VERSION ""

NS_ :

BS_:

BU_: Pegasus Marvel Laptop Stark Xavier stark ULT ECC STR DCDC

BO_ 3221225472 VECTOR__INDEPENDENT_SIG_MSG: 0 Vector__XXX
 SG_ charger_requested_current : 23|16@0+ (0.1,0) [0|255] "" Vector__XXX
 SG_ charger_requested_voltage : 7|16@0+ (0.1,0) [0|255] "" Vector__XXX
 SG_ vehicle_display_soc : 7|16@0+ (0.1,0) [0|0] "" Vector__XXX
 SG_ controller_speed : 39|16@0+ (0.1,0) [0|65535] "" Vector__XXX
 SG_ charger_is_gun_connected : 48|1@1+ (1,0) [0|2] "" Vector__XXX
 SG_ charger_type : 52|2@1+ (1,0) [0|3] "" Vector__XXX
 SG_ vehicle_state : 63|8@0+ (1,0) [0|10] "" Vector__XXX
 SG_ vehicle_calculated_odo : 23|32@0+ (0.01,0) [0|429496729.5] "Km" Vector__XXX
 SG_ vehicle_stark_ticks : 7|32@0+ (1,0) [0|-1] "" Vector__XXX
 SG_ telemetry_start_index : 39|32@0+ (1,0) [0|-1] "" Vector__XXX
 SG_ vehicle_igni_debounce_count : 39|32@0+ (1,0) [0|-1] "" Vector__XXX
 SG_ vehicle_igni_cycle_count : 7|32@0+ (1,0) [0|-1] "" Vector__XXX
 SG_ derived_param_cycle_count : 39|32@0+ (0.01,0) [0|-1] "" Vector__XXX
 SG_ battery_max_voltage : 23|16@0+ (0.1,0) [0|6553.5] "" Vector__XXX
 SG_ battery_min_voltage : 7|16@0+ (0.1,0) [0|6553.5] "" Vector__XXX
 SG_ vcu_onboard_temperature : 39|16@0+ (0.1,0) [0|6553.5] "C" Vector__XXX
 SG_ vcu_c3_box_temperature : 55|16@0+ (0.1,0) [0|6553.5] "C" Vector__XXX
 SG_ vcu_ambient_temperature : 23|16@0+ (0.1,0) [0|6553.5] "C" Vector__XXX
 SG_ vehicle_gpio_peripheral : 7|16@0+ (1,0) [0|65535] "" Vector__XXX
 SG_ vcu_uid1 : 7|64@0+ (1,0) [0|1.8446744074E+19] "" Vector__XXX
 SG_ vcu_uid2 : 7|32@0+ (1,0) [0|-1] "" Vector__XXX
 SG_ arc_reactor_status : 52|2@1+ (1,0) [0|3] "" Vector__XXX
 SG_ charger_is_charging : 50|1@1+ (1,0) [0|1] "" Vector__XXX
 SG_ charger_safe_charging_flag : 49|1@1+ (1,0) [0|1] "" Vector__XXX
 SG_ charger_disable_flag : 48|1@1+ (1,0) [0|1] "" Vector__XXX
 SG_ vehicle_sleep_flag : 51|1@1+ (1,0) [0|1] "" Vector__XXX
 SG_ derived_param_wh_km : 39|16@0+ (0.1,0) [0|6553.5] "" Vector__XXX
 SG_ vehicle_time_to_sleep : 7|32@0+ (1,0) [0|-1] "" Vector__XXX
 SG_ controller_data_type : 55|1@1+ (1,0) [0|0] "" Vector__XXX
 SG_ battery_bms_data_type : 54|1@1+ (1,0) [0|0] "" Vector__XXX
 SG_ vehicle_ecu_manifest_crc : 39|32@0+ (1,0) [0|-1] "" Vector__XXX
 SG_ vehicle_manifest_crc : 7|32@0+ (1,0) [0|-1] "" Vector__XXX
 SG_ vcu_accel_roll : 55|16@0- (0.01,0) [-32768|32767] "" Vector__XXX
 SG_ vcu_gyro_z : 39|16@0- (0.01,0) [-32768|32767] "" Vector__XXX
 SG_ vcu_gyro_y : 23|16@0- (0.01,0) [-32768|32767] "" Vector__XXX
 SG_ vcu_gyro_x : 7|16@0- (0.01,0) [-327.68|327.67] "" Vector__XXX
 SG_ vcu_accel_pitch : 55|16@0- (0.01,0) [-32768|32767] "" Vector__XXX
 SG_ vcu_accel_z : 39|16@0- (0.01,0) [-32768|32767] "" Vector__XXX
 SG_ vcu_accel_y : 23|16@0- (0.01,0) [-32768|32767] "" Vector__XXX
 SG_ vcu_accel_x : 7|16@0- (0.01,0) [-327.68|327.67] "" Vector__XXX
 SG_ vcu_mag_z : 39|16@0- (0.1,0) [-32768|32767] "" Vector__XXX
 SG_ vcu_mag_y : 23|16@0- (0.1,0) [-32768|32767] "" Vector__XXX
 SG_ vcu_mag_x : 7|16@0- (0.1,0) [-327.68|327.67] "" Vector__XXX
 SG_ vcu_angle_z : 39|16@0- (0.1,0) [-32768|32767] "" Vector__XXX
 SG_ vcu_angle_y : 23|16@0- (0.1,0) [-32768|32767] "" Vector__XXX
 SG_ vcu_angle_x : 7|16@0- (0.1,0) [-327.68|327.67] "" Vector__XXX
 SG_ error_1 : 7|64@0+ (1,0) [-32768|32767] "" Vector__XXX
 SG_ error_2 : 7|32@0+ (1,0) [-32768|32767] "" Vector__XXX
 SG_ unknown_error_1 : 39|16@0+ (1,0) [-32768|32767] "" Vector__XXX
 SG_ unknown_error_2 : 55|16@0+ (1,0) [-327.68|327.67] "" Vector__XXX
 SG_ vehicle_calculated_trip : 32|32@1+ (0.1,0) [0|0] ""  Xavier
 SG_ vehicle_ttfc : 32|16@1+ (1,0) [0|0] ""  Xavier
 SG_ vehicle_range : 16|16@1+ (0.1,0) [0|0] ""  Xavier
 SG_ vehicle_immob_state : 45|1@1+ (1,0) [0|1] "" Vector__XXX
 SG_ vehicle_thermal_runaway_flag : 22|1@1+ (1,0) [0|1] "" Vector__XXX
 SG_ vehicle_digital_lock_state : 44|1@1+ (1,0) [0|1] "" Vector__XXX
 SG_ git_shaw : 16|32@1+ (1,0) [0|-1] ""  Laptop
 SG_ device_id : 0|8@1+ (1,0) [0|255] ""  Laptop
 SG_ sim_16_20 : 0|32@1+ (1,0) [0|-1] ""  Laptop
 SG_ sim_0_16 : 0|64@1+ (1,0) [0|9.2233720369E+18] ""  Laptop
 SG_ imei : 0|64@1+ (1,0) [0|9.2233720369E+18] ""  Laptop
 SG_ certificate_state : 48|8@1+ (1,0) [0|255] ""  Laptop
 SG_ error_state : 40|8@1+ (1,0) [0|255] ""  Laptop
 SG_ system_state : 32|8@1+ (1,0) [0|255] ""  Laptop
 SG_ ota_state : 24|8@1+ (1,0) [0|255] ""  Laptop
 SG_ mqtt_publish_value : 16|8@1+ (1,0) [0|255] ""  Laptop
 SG_ http_state : 8|8@1+ (1,0) [0|255] ""  Laptop
 SG_ network_state : 0|8@1+ (1,0) [0|0] ""  Laptop
 SG_ battery_bms_temperature_9 : 16|8@1+ (1,0) [0|255] "C" Vector__XXX
 SG_ battery_bms_temperature_8 : 8|8@1+ (1,0) [0|255] "C" Vector__XXX
 SG_ battery_bms_temperature_7 : 0|8@1+ (1,0) [0|255] "C" Vector__XXX
 SG_ battery_bms_temperature_11 : 32|8@1+ (1,0) [0|255] "C" Vector__XXX
 SG_ battery_bms_temperature_10 : 24|8@1+ (1,0) [0|255] "C" Vector__XXX
 SG_ battery_bms_temperature_minimum : 40|8@1- (1,0) [-40|125] "C" Vector__XXX
 SG_ battery_bms_temperature_maximum : 48|8@1- (1,0) [-40|125] "C" Vector__XXX
 SG_ battery_bms_temperature_average : 56|8@1- (1,0) [-40|125] "C" Vector__XXX
 SG_ battery_bms_max_capacity : 0|16@1+ (0.1,0) [0|6553.5] "Ah" Vector__XXX
 SG_ battery_cmu_2_balancing_mask : 48|16@1+ (1,0) [0|65535] "" Vector__XXX
 SG_ battery_cmu_1_balancing_mask : 32|16@1+ (1,0) [0|65535] "" Vector__XXX
 SG_ battery_cmu_3_balancing_mask : 48|16@1+ (1,0) [0|65535] "" Vector__XXX
 SG_ battery_c_10_v_4 : 16|16@1+ (0.1,0) [0|6553.5] "mV" Vector__XXX
 SG_ battery_c_10_v_2 : 0|16@1+ (0.1,0) [0|6553.5] "mV" Vector__XXX
 SG_ battery_voltage_min_cmu : 32|8@1+ (1,0) [0|255] "" Vector__XXX
 SG_ battery_voltage_min_cell : 40|8@1+ (1,0) [0|255] "" Vector__XXX
 SG_ battery_voltage_max_cmu : 48|8@1+ (1,0) [0|255] "" Vector__XXX
 SG_ battery_voltage_max_cell : 56|8@1+ (1,0) [0|255] "" Vector__XXX
 SG_ battery_c_9_v_9 : 48|16@1+ (0.1,0) [0|6553.5] "mV" Vector__XXX
 SG_ battery_c_9_v_7 : 32|16@1+ (0.1,0) [0|6553.5] "mV" Vector__XXX
 SG_ battery_c_9_v_5 : 16|16@1+ (0.1,0) [0|6553.5] "mV" Vector__XXX
 SG_ battery_c_9_v_3 : 0|16@1+ (0.1,0) [0|6553.5] "mV" Vector__XXX
 SG_ battery_c_9_v_1 : 48|16@1+ (0.1,0) [0|6553.5] "mV" Vector__XXX
 SG_ battery_c_8_v_8 : 32|16@1+ (0.1,0) [0|6553.5] "mV" Vector__XXX
 SG_ battery_c_8_v_6 : 16|16@1+ (0.1,0) [0|6553.5] "mV" Vector__XXX
 SG_ battery_c_8_v_4 : 0|16@1+ (0.1,0) [0|6553.5] "mV" Vector__XXX
 SG_ battery_c_8_v_2 : 48|16@1+ (0.1,0) [0|6553.5] "mV" Vector__XXX
 SG_ battery_c_7_v_9 : 32|16@1+ (0.1,0) [0|6553.5] "mV" Vector__XXX
 SG_ battery_c_7_v_7 : 16|16@1+ (0.1,0) [0|6553.5] "mV" Vector__XXX
 SG_ battery_c_7_v_5 : 0|16@1+ (0.1,0) [0|6553.5] "mV" Vector__XXX
 SG_ battery_c_7_v_3 : 48|16@1+ (0.1,0) [0|6553.5] "mV" Vector__XXX
 SG_ battery_c_7_v_1 : 32|16@1+ (0.1,0) [0|6553.5] "mV" Vector__XXX
 SG_ battery_c_6_v_11 : 16|16@1+ (0.1,0) [0|6553.5] "mV" Vector__XXX
 SG_ battery_c_6_v_9 : 0|16@1+ (0.1,0) [0|6553.5] "mV" Vector__XXX
 SG_ battery_c_6_v_7 : 48|16@1+ (0.1,0) [0|6553.5] "mV" Vector__XXX
 SG_ battery_c_6_v_5 : 32|16@1+ (0.1,0) [0|6553.5] "mV" Vector__XXX
 SG_ battery_c_6_v_3 : 16|16@1+ (0.1,0) [0|6553.5] "mV" Vector__XXX
 SG_ battery_c_6_v_1 : 0|16@1+ (0.1,0) [0|6553.5] "mV" Vector__XXX
 SG_ battery_c_5_v_3 : 48|16@1+ (0.1,0) [0|6553.5] "mV" Vector__XXX
 SG_ battery_c_5_v_1 : 32|16@1+ (0.1,0) [0|6553.5] "mV" Vector__XXX
 SG_ battery_c_4_v_8 : 16|16@1+ (0.1,0) [0|6553.5] "mV" Vector__XXX
 SG_ battery_c_4_v_6 : 0|16@1+ (0.1,0) [0|6553.5] "mV" Vector__XXX
 SG_ battery_c_5_v_11 : 48|16@1+ (0.1,0) [0|6553.5] "mV" Vector__XXX
 SG_ battery_c_5_v_9 : 32|16@1+ (0.1,0) [0|6553.5] "mV" Vector__XXX
 SG_ battery_c_5_v_7 : 16|16@1+ (0.1,0) [0|6553.5] "mV" Vector__XXX
 SG_ battery_c_5_v_5 : 0|16@1+ (0.1,0) [0|6553.5] "mV" Vector__XXX
 SG_ controller_motor_requested_torque : 0|16@1+ (0.1,-3200) [0|0] "Nm" Vector__XXX
 SG_ controller_requested_mode : 32|8@1+ (1,0) [0|0] "" Vector__XXX
 SG_ controller_enable_signal : 40|1@1+ (1,0) [0|0] "" Vector__XXX
 SG_ controller_active_discharge_cmd : 41|1@1+ (1,0) [0|0] "" Vector__XXX
 SG_ controller_bus_status : 42|2@1+ (1,0) [0|0] "" Vector__XXX
 SG_ controller_regen_off : 10|1@1+ (1,0) [0|0] "" Vector__XXX
 SG_ battery_c_4_v_4 : 48|16@1+ (0.1,0) [0|6553.5] "mV" Vector__XXX
 SG_ battery_c_4_v_2 : 32|16@1+ (0.1,0) [0|6553.5] "mV" Vector__XXX
 SG_ battery_c_3_v_9 : 16|16@1+ (0.1,0) [0|6553.5] "mV" Vector__XXX
 SG_ battery_c_3_v_7 : 0|16@1+ (0.1,0) [0|6553.5] "mV" Vector__XXX
 SG_ battery_c_2_v_8 : 0|16@1+ (0.1,0) [0|6553.5] "mV" Vector__XXX
 SG_ battery_c_3_v_5 : 48|16@1+ (0.1,0) [0|6553.5] "mV" Vector__XXX
 SG_ battery_c_3_v_3 : 32|16@1+ (0.1,0) [0|6553.5] "mV" Vector__XXX
 SG_ battery_c_3_v_1 : 16|16@1+ (0.1,0) [0|6553.5] "mV" Vector__XXX
 SG_ battery_c_2_v_6 : 48|16@1+ (0.1,0) [0|6553.5] "mV" Vector__XXX
 SG_ battery_c_2_v_4 : 32|16@1+ (0.1,0) [0|6553.5] "mV" Vector__XXX
 SG_ battery_c_2_v_2 : 16|16@1+ (0.1,0) [0|6553.5] "mV" Vector__XXX
 SG_ battery_c_1_v_9 : 0|16@1+ (0.1,0) [0|6553.5] "mV" Vector__XXX
 SG_ battery_c_1_v_7 : 48|16@1+ (0.1,0) [0|6553.5] "mV" Vector__XXX
 SG_ battery_c_1_v_5 : 32|16@1+ (0.1,0) [0|6553.5] "mV" Vector__XXX
 SG_ battery_c_1_v_3 : 16|16@1+ (0.1,0) [0|6553.5] "mV" Vector__XXX
 SG_ battery_c_1_v_1 : 0|16@1+ (0.1,0) [0|6553.5] "mV" Vector__XXX
 SG_ vehicle_high_beam_current : 7|8@0+ (0.1,0) [0|0] "" Vector__XXX
 SG_ vehicle_low_beam_current : 15|8@0+ (0.1,0) [0|0] "" Vector__XXX
 SG_ vehicle_right_lamp_current : 23|8@0+ (0.1,0) [0|0] "" Vector__XXX
 SG_ vehicle_left_lamp_current : 31|8@0+ (0.1,0) [0|0] "" Vector__XXX
 SG_ vehicle_radiator_fan_current : 47|8@0+ (0.1,0) [0|0] "" Vector__XXX
 SG_ vehicle_controller_power_current : 55|8@0+ (0.1,0) [0|0] "" Vector__XXX
 SG_ vehicle_brake_pump_current : 39|8@0+ (0.1,0) [0|0] "" Vector__XXX
 SG_ vehicle_wiper_current : 63|8@0+ (0.1,0) [0|0] "" Vector__XXX
 SG_ vehicle_bms_current : 15|8@0+ (0.01,0) [0|0] "" Vector__XXX
 SG_ vehicle_heating_element2_current : 7|8@0+ (0.1,0) [0|0] "" Vector__XXX
 SG_ vehicle_fc_contactor_current : 23|8@0+ (0.1,0) [0|0] "" Vector__XXX
 SG_ vehicle_brake_light_current : 31|8@0+ (0.1,0) [0|0] "" Vector__XXX
 SG_ vehicle_telemetry_current : 39|8@0+ (0.01,0) [0|0] "" Vector__XXX
 SG_ vehicle_cluster_current : 47|8@0+ (0.01,0) [0|0] "" Vector__XXX
 SG_ vehicle_number_plate_current : 55|8@0+ (0.1,0) [0|0] "" Vector__XXX
 SG_ vehicle_brake_enable_current : 63|8@0+ (0.1,0) [0|0] "" Vector__XXX
 SG_ vehicle_ar_fan_current : 47|8@0+ (0.1,0) [0|0] "" Vector__XXX
 SG_ vehicle_ar_pump_current : 39|8@0+ (0.1,0) [0|0] "" Vector__XXX
 SG_ vehicle_cabin_light_current : 7|8@0+ (0.1,0) [0|0] "" Vector__XXX
 SG_ vehicle_heating_element_current : 31|8@0+ (0.1,0) [0|0] "" Vector__XXX
 SG_ vehicle_peltier_current : 15|8@0+ (0.1,0) [0|0] "" Vector__XXX
 SG_ vehicle_reverse_light_current : 23|8@0+ (0.1,0) [0|0] "" Vector__XXX
 SG_ vcu_mosfet_1_voltage : 7|8@0+ (0.1,0) [0|0] "" Vector__XXX
 SG_ vcu_mosfet_2_voltage : 15|8@0+ (0.1,0) [0|0] "" Vector__XXX
 SG_ vcu_mosfet_7_voltage : 39|8@0+ (0.1,0) [0|0] "" Vector__XXX
 SG_ vcu_mosfet_8_voltage : 47|8@0+ (0.1,0) [0|0] "" Vector__XXX
 SG_ vcu_mosfet_5_voltage : 23|8@0+ (0.1,0) [0|0] "" Vector__XXX
 SG_ vcu_mosfet_6_voltage : 31|8@0+ (0.1,0) [0|0] "" Vector__XXX
 SG_ vcu_mosfet_1_temperature : 7|8@0+ (1,0) [0|0] "" Vector__XXX
 SG_ vcu_mosfet_2_temperature : 15|8@0+ (1,0) [0|0] "" Vector__XXX
 SG_ vcu_mosfet_6_temperature : 31|8@0+ (1,0) [0|0] "" Vector__XXX
 SG_ vcu_mosfet_7_temperature : 39|8@0+ (1,0) [0|0] "" Vector__XXX
 SG_ vcu_mosfet_5_temperature : 23|8@0+ (1,0) [0|0] "" Vector__XXX
 SG_ vcu_mosfet_8_temperature : 47|8@0+ (1,0) [0|0] "" Vector__XXX
 SG_ vehicle_gpio_peripheral2 : 7|16@0+ (1,0) [0|0] "" Vector__XXX
 SG_ vcu_mcu_reference_voltage : 47|16@0+ (1,0) [0|0] "" Vector__XXX
 SG_ vcu_high_current_flag : 39|32@0+ (1,0) [0|0] "" Vector__XXX
 SG_ vcu_short_circuit_flag : 7|32@0+ (1,0) [0|0] "" Vector__XXX
 SG_ vcu_over_temp_flag : 39|32@0+ (1,0) [0|0] "" Vector__XXX
 SG_ vcu_under_voltage_flag : 7|32@0+ (1,0) [0|0] "" Vector__XXX
 SG_ vcu_spi_hal_state : 55|8@0+ (1,0) [0|255] "" Vector__XXX
 SG_ vcu_spi_state : 47|8@0+ (1,0) [0|255] "" Vector__XXX
 SG_ vcu_spi_error_flag : 39|8@0+ (1,0) [0|255] "" Vector__XXX
 SG_ vcu_can_tx_error_count : 31|8@0+ (1,0) [0|255] "" Vector__XXX
 SG_ vcu_can_rx_error_count : 23|8@0+ (1,0) [0|255] "" Vector__XXX
 SG_ vcu_can_esr_flags : 15|8@0+ (1,0) [0|255] "" Vector__XXX
 SG_ vcu_can_error_flag : 7|8@0+ (1,0) [0|255] "" Vector__XXX
 SG_ vcu_open_circuit_flag : 39|32@0+ (1,0) [0|0] "" Vector__XXX
 SG_ vcu_peripheral_failure_flag : 7|32@0+ (1,0) [0|0] "" Vector__XXX

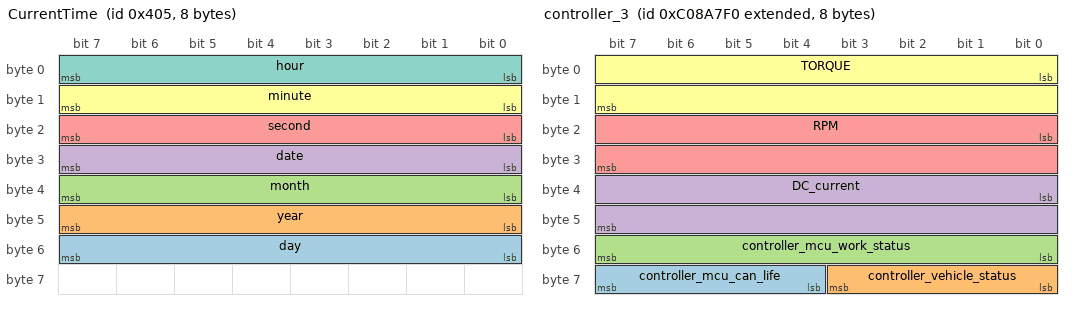
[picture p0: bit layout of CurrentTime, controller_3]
BO_ 1029 CurrentTime: 8 Xavier
 SG_ day : 48|8@1+ (1,0) [0|255] ""  Laptop,Stark
 SG_ year : 40|8@1+ (1,0) [0|255] ""  Laptop,Stark
 SG_ month : 32|8@1+ (1,0) [0|255] ""  Laptop,Stark
 SG_ date : 24|8@1+ (1,0) [0|255] ""  Laptop,Stark
 SG_ second : 16|8@1+ (1,0) [0|255] ""  Laptop,Stark
 SG_ minute : 8|8@1+ (1,0) [0|255] ""  Laptop,Stark
 SG_ hour : 0|8@1+ (1,0) [0|255] ""  Laptop,Stark

BO_ 2349377520 controller_3: 8 Vector__XXX
 SG_ controller_mcu_can_life : 60|4@1+ (1,0) [0|0] "" Vector__XXX
 SG_ controller_vehicle_status : 56|4@1+ (1,0) [0|0] "" Vector__XXX
 SG_ controller_mcu_work_status : 48|8@1+ (1,0) [0|0] "" Vector__XXX
 SG_ DC_current : 32|16@1+ (0.1,-3200) [0|0] "A" Vector__XXX
 SG_ RPM : 16|16@1+ (1,-32000) [0|0] "rpm" Vector__XXX
 SG_ TORQUE : 0|16@1+ (0.1,-3200) [0|0] "Nm" Vector__XXX

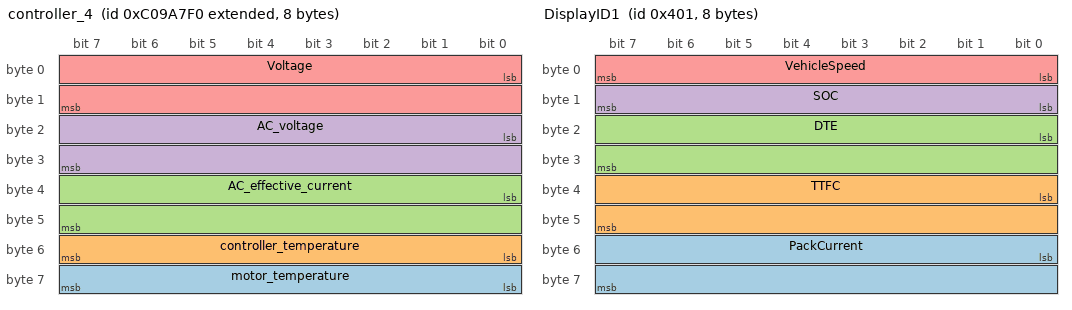
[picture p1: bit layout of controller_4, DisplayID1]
BO_ 2349443056 controller_4: 8 Vector__XXX
 SG_ motor_temperature : 56|8@1+ (1,-40) [0|0] "  C" Vector__XXX
 SG_ controller_temperature : 48|8@1+ (1,-40) [0|0] "  C" Vector__XXX
 SG_ AC_effective_current : 32|16@1+ (0.1,-3200) [0|0] "A" Vector__XXX
 SG_ AC_voltage : 16|16@1+ (0.1,0) [0|0] "V" Vector__XXX
 SG_ Voltage : 0|16@1+ (0.1,0) [0|0] "V" Vector__XXX

BO_ 2349508592 controller_5: 8 Vector__XXX
 SG_ controller_error_count : 56|3@1+ (1,0) [0|0] "" Vector__XXX
 SG_ controller_brake_status : 62|1@1+ (1,0) [0|0] "" Vector__XXX

BO_ 1808 controller_6: 8 Vector__XXX
 SG_ throttle_percentage : 0|8@1+ (1,0) [0|100] "%" Vector__XXX
 SG_ throttle_voltage : 24|8@1+ (0.1,0) [0|10] "V" Vector__XXX

BO_ 1025 DisplayID1: 8 Stark
 SG_ PackCurrent : 48|16@1+ (0.1,0) [0|0] ""  Xavier
 SG_ TTFC : 32|16@1+ (1,0) [0|0] ""  Xavier
 SG_ DTE : 16|16@1+ (0.1,0) [0|0] ""  Xavier
 SG_ SOC : 8|8@1+ (1,0) [0|100] ""  Xavier
 SG_ VehicleSpeed : 0|8@1+ (1,0) [0|0] ""  Xavier

BO_ 1026 OdoAndTripDisplay: 8 Stark
 SG_ Trip : 32|32@1+ (0.1,0) [0|0] ""  Xavier
 SG_ ODO : 0|32@1- (0.1,0) [0|0] ""  Xavier

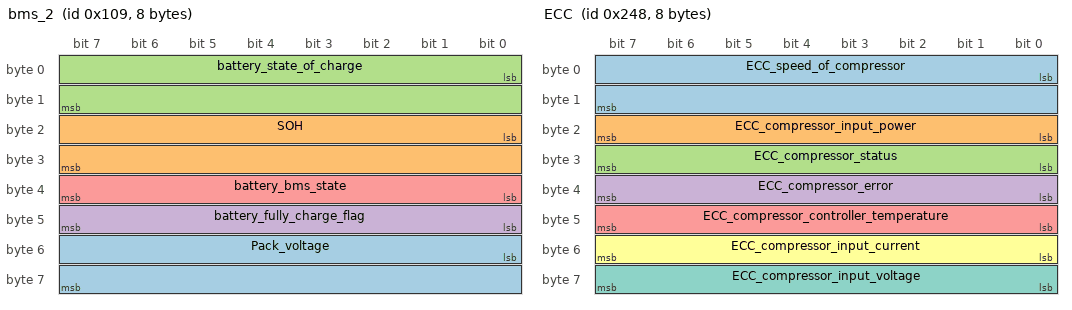
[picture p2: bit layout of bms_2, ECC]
BO_ 265 bms_2: 8 Marvel
 SG_ Pack_voltage : 48|16@1+ (0.1,0) [0|6553.5] "V" Vector__XXX
 SG_ SOH : 16|16@1+ (0.01,0) [0|655.35] "%" Vector__XXX
 SG_ battery_state_of_charge : 0|16@1+ (0.01,0) [0|655.35] "%" Vector__XXX
 SG_ battery_fully_charge_flag : 40|8@1+ (1,0) [0|255] "" Vector__XXX
 SG_ battery_bms_state : 32|8@1+ (1,0) [0|255] "" Vector__XXX

BO_ 584 ECC: 8 ECC
 SG_ ECC_speed_of_compressor : 0|16@1+ (1,0) [0|65534] "rpm"  ECC
 SG_ ECC_compressor_input_power : 16|8@1+ (0.1,0) [0|25.4] "kW"  ECC
 SG_ ECC_compressor_status : 24|8@1+ (1,0) [0|3] ""  ECC
 SG_ ECC_compressor_error : 32|8@1+ (1,0) [0|254] ""  ECC
 SG_ ECC_compressor_controller_temperature : 40|8@1+ (1,-40) [-40|214] "C"  ECC
 SG_ ECC_compressor_input_current : 48|8@1+ (0.1,0) [0|25.4] "A"  ECC
 SG_ ECC_compressor_input_voltage : 56|8@1+ (4,0) [0|1060] "V"  ECC

BO_ 2147485697 STR: 8 STR
 SG_ Steering_angle : 16|16@1+ (1,0) [0|65534] ""  STR

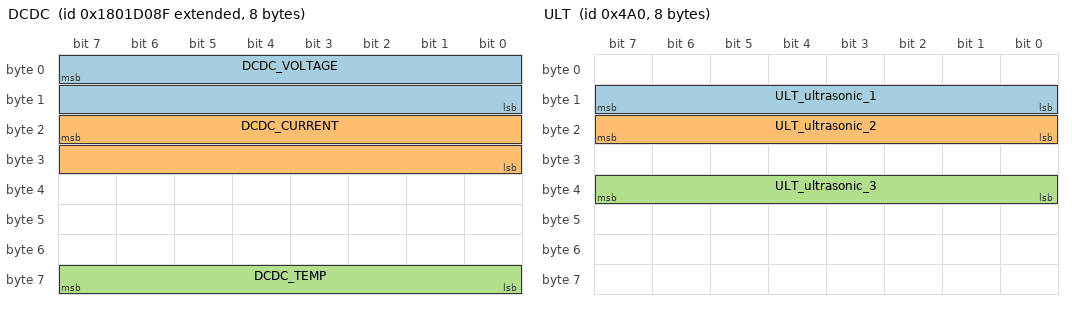
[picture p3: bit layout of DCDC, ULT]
BO_ 2550255759 DCDC: 8 DCDC
 SG_ DCDC_VOLTAGE : 7|16@0+ (0.1,0) [0|6553.4] "V"  DCDC
 SG_ DCDC_CURRENT : 23|16@0+ (0.1,0) [0|6553.4] "A"  DCDC
 SG_ DCDC_TEMP : 63|8@0+ (1,-40) [0|254] "C"  DCDC

BO_ 1184 ULT: 8 ULT
 SG_ ULT_ultrasonic_1 : 8|8@1+ (1,0) [0|254] "cm"  ULT
 SG_ ULT_ultrasonic_2 : 16|8@1+ (1,0) [0|254] "cm"  ULT
 SG_ ULT_ultrasonic_3 : 32|8@1+ (1,0) [0|254] "cm"  ULT

BO_ 1538 VehicleState: 8 Stark
 SG_ VehicleState : 48|8@1+ (1,0) [0|0] ""  Xavier

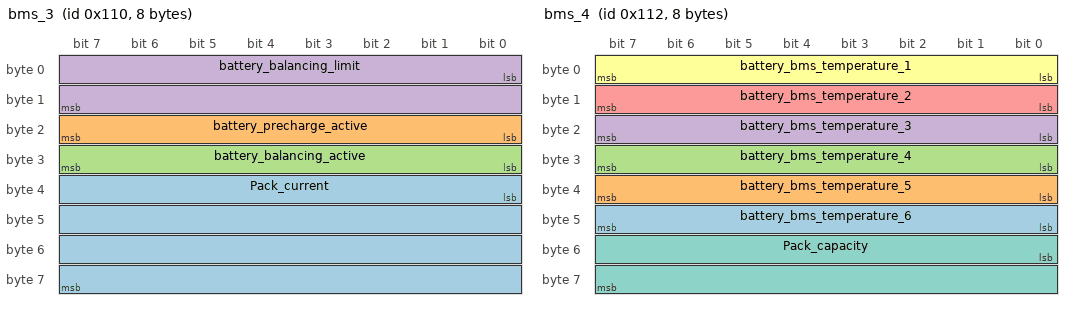
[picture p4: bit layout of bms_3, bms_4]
BO_ 272 bms_3: 8 Vector__XXX
 SG_ Pack_current : 32|32@1- (1E-05,0) [-21474836.48|21474836.47] "A" Vector__XXX
 SG_ battery_precharge_active : 16|8@1+ (1,0) [0|255] "" Vector__XXX
 SG_ battery_balancing_active : 24|8@1+ (1,0) [0|255] "" Vector__XXX
 SG_ battery_balancing_limit : 0|16@1+ (0.1,0) [0|65535] "mV" Vector__XXX

BO_ 274 bms_4: 8 Vector__XXX
 SG_ battery_bms_temperature_6 : 40|8@1+ (1,0) [0|255] "C" Vector__XXX
 SG_ battery_bms_temperature_5 : 32|8@1+ (1,0) [0|255] "C" Vector__XXX
 SG_ battery_bms_temperature_4 : 24|8@1+ (1,0) [0|255] "C" Vector__XXX
 SG_ battery_bms_temperature_3 : 16|8@1+ (1,0) [0|255] "C" Vector__XXX
 SG_ battery_bms_temperature_2 : 8|8@1+ (1,0) [0|255] "C" Vector__XXX
 SG_ battery_bms_temperature_1 : 0|8@1+ (1,0) [0|255] "C" Vector__XXX
 SG_ Pack_capacity : 48|16@1- (0.1,0) [0|6553.5] "Ah" Vector__XXX

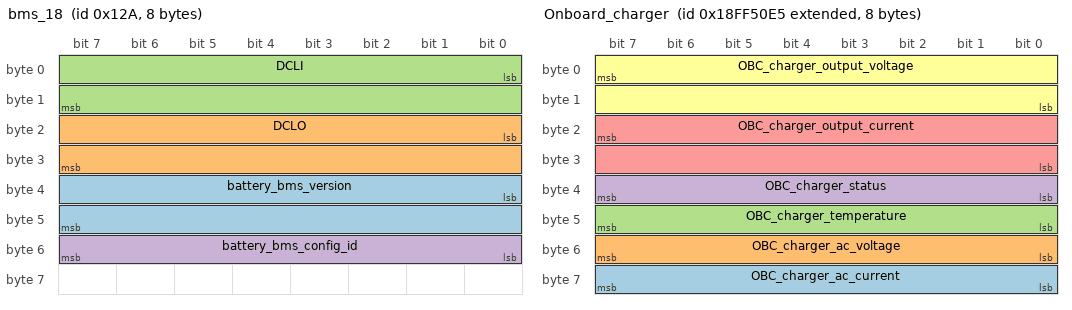
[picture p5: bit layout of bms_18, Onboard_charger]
BO_ 298 bms_18: 8 Vector__XXX
 SG_ battery_bms_version : 32|16@1+ (1,0) [0|65535] "" Vector__XXX
 SG_ DCLO : 16|16@1- (0.1,0) [-3276.8|3276.7] "A" Vector__XXX
 SG_ DCLI : 0|16@1- (0.1,0) [-3276.8|3276.7] "A" Vector__XXX
 SG_ battery_bms_config_id : 48|8@1- (1,0) [-128|127] "" Vector__XXX

BO_ 2566869221 Onboard_charger: 8 Vector__XXX
 SG_ OBC_charger_ac_current : 63|8@0+ (0.1,0) [0|255] "" Vector__XXX
 SG_ OBC_charger_ac_voltage : 55|8@0+ (1,0) [0|255] "" Vector__XXX
 SG_ OBC_charger_temperature : 47|8@0+ (1,0) [0|255] "" Vector__XXX
 SG_ OBC_charger_status : 39|8@0+ (1,0) [0|255] "" Vector__XXX
 SG_ OBC_charger_output_current : 23|16@0+ (0.1,0) [0|255] "" Vector__XXX
 SG_ OBC_charger_output_voltage : 7|16@0+ (0.1,0) [0|255] "" Vector__XXX

BO_ 1829 controller_1: 2 Vector__XXX
 SG_ Brake_voltage : 8|8@1+ (0.1,0) [0|0] "V" Vector__XXX
 SG_ Brake_percentage : 0|8@1+ (1,0) [0|0] "%" Vector__XXX

BO_ 263 bms_0: 8 Marvel
 SG_ battery_bms_requested_voltage : 7|16@0+ (0.1,0) [0|65535] "V" Vector__XXX
 SG_ battery_bms_requested_current : 23|16@0+ (0.1,0) [0|6553.5] "" Vector__XXX

BO_ 336 BalancingMask: 8 Vector__XXX
 SG_ BalancingMask0 : 0|64@1+ (1,0) [0|1.8446744074E+19] "" Vector__XXX

BO_ 337 BalancingMask1: 8 Vector__XXX
 SG_ BalancingMask1 : 0|64@1+ (1,0) [0|1.8446744074E+19] "" Vector__XXX

BO_ 342 BC_Dynamic_inst: 8 Vector__XXX
 SG_ dynamicLimitOut_Inst : 16|16@1+ (0.1,0) [0|0] "A" Vector__XXX
 SG_ dynamicLimitIn_Inst : 0|16@1+ (0.1,0) [0|0] "" Vector__XXX

BO_ 299 BF_CCM_CMU_Counter: 8 Vector__XXX
 SG_ cycleCount : 48|16@1+ (1,0) [0|0] "" Vector__XXX
 SG_ mcu_counter : 16|16@1+ (1,0) [0|0] "" Vector__XXX

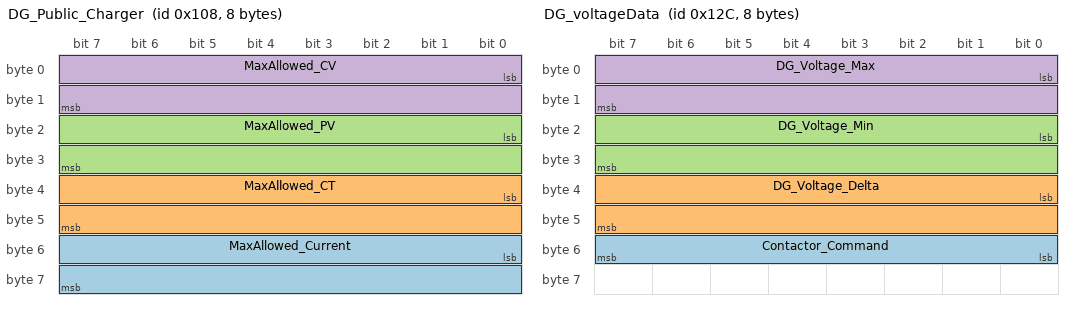
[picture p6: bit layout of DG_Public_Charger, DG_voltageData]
BO_ 264 DG_Public_Charger: 8 Vector__XXX
 SG_ MaxAllowed_Current : 48|16@1+ (1,0) [0|0] "" Vector__XXX
 SG_ MaxAllowed_CT : 32|16@1+ (1,0) [0|0] "mV" Vector__XXX
 SG_ MaxAllowed_PV : 16|16@1+ (1,0) [0|0] "mV" Vector__XXX
 SG_ MaxAllowed_CV : 0|16@1+ (1,0) [0|0] "mV" Vector__XXX

BO_ 300 DG_voltageData: 8 Vector__XXX
 SG_ Contactor_Command : 48|8@1+ (1,0) [0|0] "" Vector__XXX
 SG_ DG_Voltage_Delta : 32|16@1+ (0.1,0) [0|0] "mV" Vector__XXX
 SG_ DG_Voltage_Min : 16|16@1+ (0.1,0) [0|0] "mV" Vector__XXX
 SG_ DG_Voltage_Max : 0|16@1+ (0.1,0) [0|0] "mV" Vector__XXX

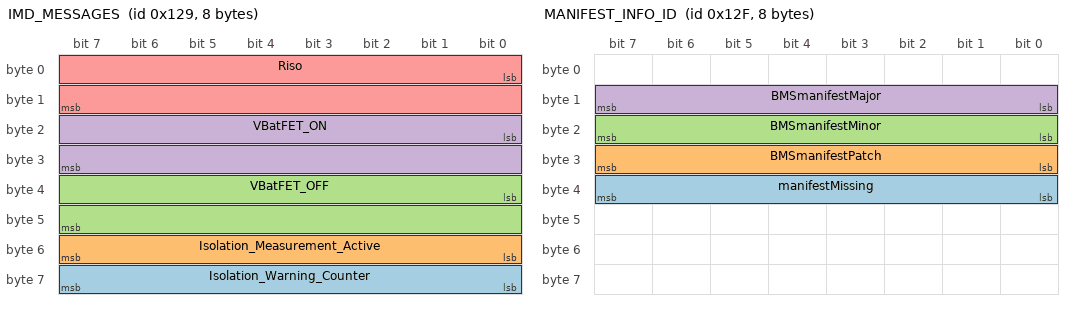
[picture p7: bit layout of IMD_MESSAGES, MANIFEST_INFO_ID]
BO_ 297 IMD_MESSAGES: 8 Vector__XXX
 SG_ Isolation_Warning_Counter : 56|8@1+ (1,0) [0|255] "" Vector__XXX
 SG_ Isolation_Measurement_Active : 48|8@1+ (1,0) [0|255] "" Vector__XXX
 SG_ VBatFET_OFF : 32|16@1- (0.01,0) [-327.68|327.67] "V" Vector__XXX
 SG_ VBatFET_ON : 16|16@1- (0.01,0) [-327.68|327.67] "V" Vector__XXX
 SG_ Riso : 0|16@1+ (0.01,0) [0|655.35] "M ohm" Vector__XXX

BO_ 302 IR_PARAM_1: 8 Vector__XXX
 SG_ IR_Value : 0|32@1+ (10000,0) [0|0] "" Vector__XXX

BO_ 303 MANIFEST_INFO_ID: 8 Vector__XXX
 SG_ manifestMissing : 32|8@1+ (1,0) [0|255] "" Vector__XXX
 SG_ BMSmanifestPatch : 24|8@1+ (1,0) [0|255] "" Vector__XXX
 SG_ BMSmanifestMinor : 16|8@1+ (1,0) [0|255] "" Vector__XXX
 SG_ BMSmanifestMajor : 8|8@1+ (1,0) [0|255] "" Vector__XXX

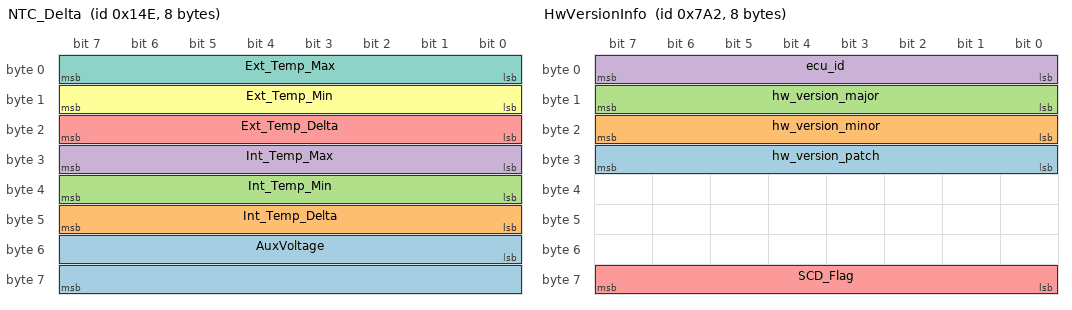
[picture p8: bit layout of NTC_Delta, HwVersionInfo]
BO_ 334 NTC_Delta: 8 Vector__XXX
 SG_ AuxVoltage : 48|16@1+ (0.1,0) [0|655.35] "V" Vector__XXX
 SG_ Int_Temp_Delta : 40|8@1- (1,0) [-128|127] "degC" Vector__XXX
 SG_ Int_Temp_Min : 32|8@1- (1,0) [-128|127] "degC" Vector__XXX
 SG_ Int_Temp_Max : 24|8@1- (1,0) [-128|127] "degC" Vector__XXX
 SG_ Ext_Temp_Delta : 16|8@1- (1,0) [-128|127] "degC" Vector__XXX
 SG_ Ext_Temp_Min : 8|8@1- (1,0) [-128|127] "degC" Vector__XXX
 SG_ Ext_Temp_Max : 0|8@1- (1,0) [-128|127] "degC" Vector__XXX

BO_ 1954 HwVersionInfo: 8 Xavier
 SG_ hw_version_patch : 24|8@1+ (1,0) [0|255] ""  Laptop,Stark
 SG_ hw_version_minor : 16|8@1+ (1,0) [0|255] ""  Laptop,Stark
 SG_ hw_version_major : 8|8@1+ (1,0) [0|255] ""  Laptop,Stark
 SG_ ecu_id : 0|8@1+ (1,0) [0|255] ""  Stark,Laptop
 SG_ SCD_Flag : 56|8@1+ (1,0) [0|0] ""  Stark,Laptop

BO_ 262 Shutdown_ack_flag: 1 Vector__XXX
 SG_ BMS_SD_ack_flag : 0|8@1+ (1,0) [0|0] "" Vector__XXX

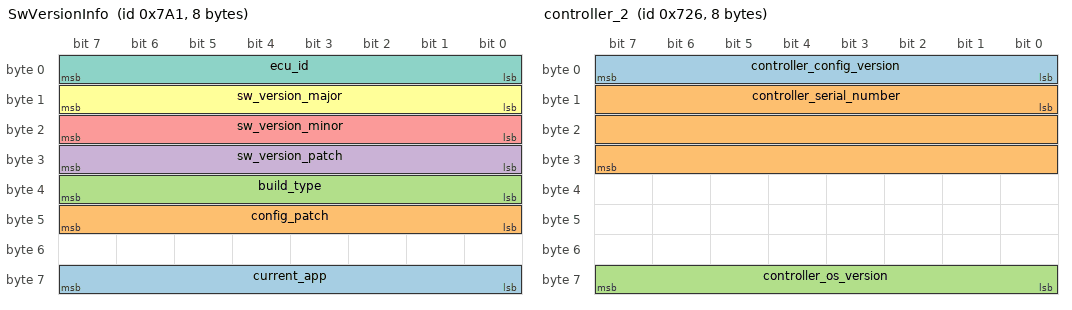
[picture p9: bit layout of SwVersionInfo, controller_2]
BO_ 1953 SwVersionInfo: 8 Xavier
 SG_ current_app : 56|8@1+ (1,0) [0|255] ""  Laptop,Stark
 SG_ config_patch : 40|8@1+ (1,0) [0|255] ""  Laptop,Stark
 SG_ build_type : 32|8@1+ (1,0) [0|255] ""  Laptop,Stark
 SG_ sw_version_patch : 24|8@1+ (1,0) [0|255] ""  Laptop,Stark
 SG_ sw_version_minor : 16|8@1+ (1,0) [0|255] ""  Laptop,Stark
 SG_ sw_version_major : 8|8@1+ (1,0) [0|255] ""  Laptop,Stark
 SG_ ecu_id : 0|8@1+ (1,0) [0|255] ""  Laptop,Stark

BO_ 1830 controller_2: 8 Vector__XXX
 SG_ controller_config_version : 0|8@1+ (1,0) [0|0] "" Vector__XXX
 SG_ controller_serial_number : 8|24@1+ (1,0) [0|0] "" Vector__XXX
 SG_ controller_os_version : 56|8@1+ (1,0) [0|0] "" Vector__XXX

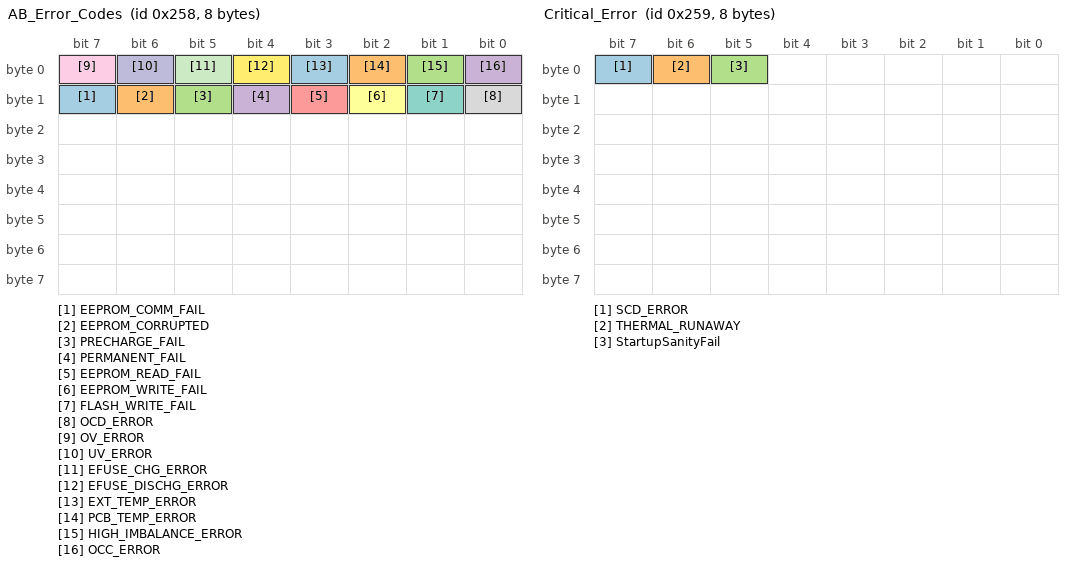
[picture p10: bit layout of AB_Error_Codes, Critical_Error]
BO_ 600 AB_Error_Codes: 8 Vector__XXX
 SG_ EEPROM_COMM_FAIL : 15|1@1+ (1,0) [0|0] "" Vector__XXX
 SG_ EEPROM_CORRUPTED : 14|1@1+ (1,0) [0|0] "" Vector__XXX
 SG_ PRECHARGE_FAIL : 13|1@1+ (1,0) [0|0] "" Vector__XXX
 SG_ PERMANENT_FAIL : 12|1@1+ (1,0) [0|0] "" Vector__XXX
 SG_ EEPROM_READ_FAIL : 11|1@1+ (1,0) [0|0] "" Vector__XXX
 SG_ EEPROM_WRITE_FAIL : 10|1@1+ (1,0) [0|0] "" Vector__XXX
 SG_ FLASH_WRITE_FAIL : 9|1@1+ (1,0) [0|0] "" Vector__XXX
 SG_ OCD_ERROR : 8|1@1+ (1,0) [0|0] "" Vector__XXX
 SG_ OV_ERROR : 7|1@1+ (1,0) [0|0] "" Vector__XXX
 SG_ UV_ERROR : 6|1@1+ (1,0) [0|0] "" Vector__XXX
 SG_ EFUSE_CHG_ERROR : 5|1@1+ (1,0) [0|0] "" Vector__XXX
 SG_ EFUSE_DISCHG_ERROR : 4|1@1+ (1,0) [0|0] "" Vector__XXX
 SG_ EXT_TEMP_ERROR : 3|1@1+ (1,0) [0|0] "" Vector__XXX
 SG_ PCB_TEMP_ERROR : 2|1@1+ (1,0) [0|0] "" Vector__XXX
 SG_ HIGH_IMBALANCE_ERROR : 1|1@1+ (1,0) [0|0] "" Vector__XXX
 SG_ OCC_ERROR : 0|1@1+ (1,0) [0|0] "" Vector__XXX

BO_ 601 Critical_Error: 8 Vector__XXX
 SG_ SCD_ERROR : 7|1@1+ (1,0) [0|0] "" Vector__XXX
 SG_ THERMAL_RUNAWAY : 6|1@1+ (1,0) [0|0] "" Vector__XXX
 SG_ StartupSanityFail : 5|1@1+ (1,0) [0|0] "" Vector__XXX

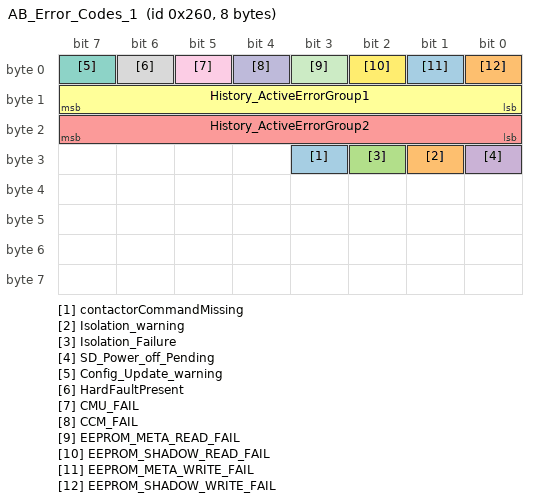
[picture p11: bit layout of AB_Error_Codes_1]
BO_ 608 AB_Error_Codes_1: 8 Vector__XXX
 SG_ contactorCommandMissing : 27|1@1+ (1,0) [0|1] "" Vector__XXX
 SG_ Isolation_warning : 25|1@1+ (1,0) [0|1] "" Vector__XXX
 SG_ Isolation_Failure : 26|1@1+ (1,0) [0|1] "" Vector__XXX
 SG_ SD_Power_off_Pending : 24|1@1+ (1,0) [0|0] "" Vector__XXX
 SG_ History_ActiveErrorGroup2 : 16|8@1+ (1,0) [0|0] "" Vector__XXX
 SG_ History_ActiveErrorGroup1 : 8|8@1+ (1,0) [0|0] "" Vector__XXX
 SG_ Config_Update_warning : 7|1@1+ (1,0) [0|0] "" Vector__XXX
 SG_ HardFaultPresent : 6|1@1+ (1,0) [0|0] "" Vector__XXX
 SG_ CMU_FAIL : 5|1@1+ (1,0) [0|0] "" Vector__XXX
 SG_ CCM_FAIL : 4|1@1+ (1,0) [0|0] "" Vector__XXX
 SG_ EEPROM_META_READ_FAIL : 3|1@1+ (1,0) [0|0] "" Vector__XXX
 SG_ EEPROM_SHADOW_READ_FAIL : 2|1@1+ (1,0) [0|0] "" Vector__XXX
 SG_ EEPROM_META_WRITE_FAIL : 1|1@1+ (1,0) [0|0] "" Vector__XXX
 SG_ EEPROM_SHADOW_WRITE_FAIL : 0|1@1+ (1,0) [0|0] "" Vector__XXX

BO_ 1542 id606: 8 Vector__XXX
 SG_ vehicle_aux_charing_flag : 7|8@0+ (1,0) [0|3] "" Vector__XXX
 SG_ vehicle_aux_battery_voltage : 15|16@0+ (0.01,0) [0|655.35] "" Vector__XXX

BO_ 1559 id617: 8 Vector__XXX
 SG_ controller_error : 7|64@0+ (1,0) [0|0] "" Vector__XXX

BO_ 1547 id60B: 8 Vector__XXX
 SG_ brake_light : 1|1@0+ (1,0) [0|1] "" Vector__XXX

CM_ SG_ 3221225472 controller_regen_off "   ռ    ־";
CM_ BO_ 1029 "1

";
CM_ BO_ 2349377520 "2";
CM_ SG_ 2349377520 controller_vehicle_status "MCU  ǰ  λ";
CM_ SG_ 2349377520 DC_current "ֱ  ĸ ߵ   ";
CM_ SG_ 2349377520 RPM "   ʵ  ת  ";
CM_ SG_ 2349377520 TORQUE "      Ť  ";
CM_ BO_ 2349443056 "3";
CM_ SG_ 2349443056 motor_temperature "    ¶ ";
CM_ SG_ 2349443056 controller_temperature "          ¶ ";
CM_ SG_ 2349443056 AC_effective_current "      Чֵ";
CM_ SG_ 2349443056 AC_voltage "MCU      ѹ";
CM_ SG_ 2349443056 Voltage "MCUֱ    ѹ";
CM_ BO_ 2349508592 "4";
CM_ BO_ 1808 "5
";
CM_ BO_ 265 "8";
CM_ BO_ 272 "14
";
CM_ BO_ 274 "15";
CM_ BO_ 298 "16
";
CM_ BO_ 2566869221 "17";
CM_ BO_ 1829 "18";
CM_ SG_ 1829 Brake_voltage "ɲ    ѹ";
CM_ SG_ 1829 Brake_percentage "ɲ   ٷֱ ";
CM_ BO_ 263 "19";
CM_ BO_ 1954 "33";
CM_ BO_ 1953 "31";
CM_ BO_ 1830 "34";
CM_ SG_ 1830 controller_config_version "   ð汾";
VAL_ 2349377520 controller_vehicle_status 0 "N" 1 "S" 2 "R" 3 "E" 4 "H" ;
